AUTOSAR XML (schema 4-3-0)
package /CollisionDetectionApplicationLayer/CompositionPackage
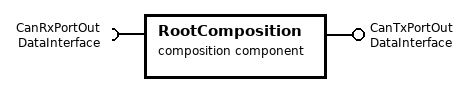
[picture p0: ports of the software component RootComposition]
  composition sw component type RootComposition
    provide port CanTxPortOut: provided-interface=DataInterface
    require port CanRxPortOut: required-interface=DataInterface
    10 x component:
      collisiondetectionSWC: type=CollisionDetectionSWC
      ultrasonicSWC: type=UltraSonicSWC
      cantranslateSWC: type=CanTranslateSWC
      RearLedSWC: type=LEDActuatorSWC
      FrontLedSWC: type=LEDActuatorSWC
      modeManagerInitSWC: type=ModeManagerSWC
      ioHwAb: type=IoHwAb
      ecuM: type=EcuM
      comM: type=ComM
      bswM: type=BswM
    connect ioHwAb.DigitalFrontLED -> FrontLedSWC.DigitalLED
    connect ioHwAb.DigitalRearLED -> RearLedSWC.DigitalLED
    connect ioHwAb.DigitalSonarTrig -> ultrasonicSWC.SonarTrig
    connect ioHwAb.DigitalSonarEcho -> ultrasonicSWC.SonarEcho
    connect ultrasonicSWC.SonarSend -> cantranslateSWC.SonarRecv
    connect ultrasonicSWC.SonarSend -> collisiondetectionSWC.SonarRecv
    connect collisiondetectionSWC.FrontStatus -> FrontLedSWC.Status
    connect collisiondetectionSWC.RearStatus -> RearLedSWC.Status
    connect ecuM.currentMode -> modeManagerInitSWC.Mode
    connect modeManagerInitSWC.ComMControl -> bswM.modeRequestPort_SwcStartCommunication
    connect ecuM.SR_User -> modeManagerInitSWC.RunControl
    delegate cantranslateSWC.CanTxPort <-> outer port CanTxPortOut
    delegate cantranslateSWC.CanRxPort <-> outer port CanRxPortOut
